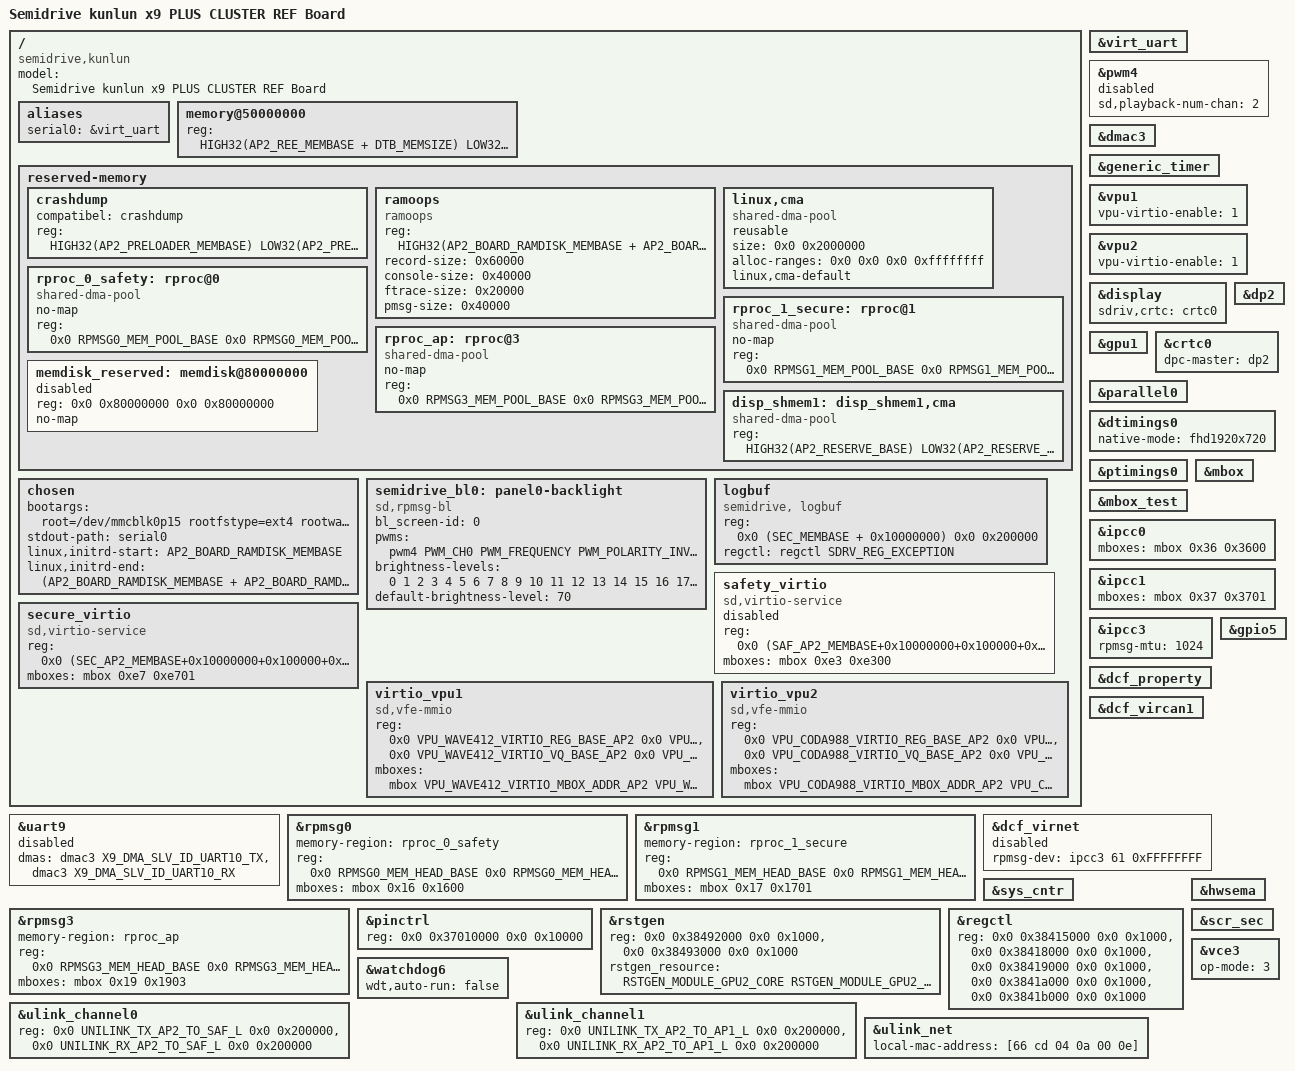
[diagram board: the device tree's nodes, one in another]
/*
 * Semidrive kunlun platform DTS file
 *
 * Copyright (C) 2019, Semidrive  Communications Inc.
 *
 * This file is licensed under a dual GPLv2 or X11 license.
 */

/dts-v1/;

#include "x9_high-plus_cluster.dtsi"
#include "x9_high-plus_ref_cluster-clk-ctrl.dtsi"
#include "lcd-timings.dtsi"
#include <dt-bindings/pinctrl/pins-sdx9.h>
#include <dt-bindings/memmap/x9_high-plus/projects/serdes_virt_emmc/image_cfg.h>
#include <dt-bindings/rpmsg/sd,x9hp-ap2.h>
#include <dt-bindings/backlight/sdrv_backlight.h>
#include <dt-bindings/memmap/mem_share.h>
#include <dt-bindings/soc/sdrv-virtio.h>
#include <dt-bindings/soc/sdrv-unilink-x9hp.h>

/ {
	model = "Semidrive kunlun x9 PLUS CLUSTER REF Board";

	compatible = "semidrive,kunlun";

	aliases {
		serial0 = &virt_uart;
	};

	memory@50000000 {
		device_type = "memory";
		reg = <HIGH32(AP2_REE_MEMBASE + DTB_MEMSIZE) LOW32(AP2_REE_MEMBASE + DTB_MEMSIZE) HIGH32(AP2_KERNEL_MEMSIZE) LOW32(AP2_KERNEL_MEMSIZE) \
			HIGH32(AP2_RESERVE_BASE) LOW32(AP2_RESERVE_BASE) HIGH32(AP2_RESERVE_SIZE) LOW32(AP2_RESERVE_SIZE)>;
	};

	reserved-memory {
		#address-cells = <2>;
		#size-cells = <2>;
		ranges;

		crashdump {
			/* reserve preloader mem for crashdump */
			compatibel = "crashdump";
			reg = <HIGH32(AP2_PRELOADER_MEMBASE) LOW32(AP2_PRELOADER_MEMBASE) 0 AP2_PRELOADER_MEMSIZE>;
		};

		ramoops {
			compatible = "ramoops";
			reg = <HIGH32(AP2_BOARD_RAMDISK_MEMBASE + AP2_BOARD_RAMDISK_MEMSIZE + 0x1000000)
				LOW32(AP2_BOARD_RAMDISK_MEMBASE + AP2_BOARD_RAMDISK_MEMSIZE + 0x1000000) 0x0 0x100000>;
			record-size = <0x60000>;
			console-size = <0x40000>;
			ftrace-size = <0x20000>;
			pmsg-size = <0x40000>;
		};

		/* Default Common CMA Pool */
		/* QUIRK: Must be kept in the lower 4096 MiBs of DRAM banks for VE */
		linux,cma {
			compatible = "shared-dma-pool";
			reusable;
			size = <0x0 0x2000000>; /* 32MB */
			/* 4GB maximum in case of 32-bit only capable devices */
			alloc-ranges = <0x0 0x0 0x0 0xffffffff>;
			linux,cma-default;
		};

		rproc_0_safety: rproc@0 {
			compatible = "shared-dma-pool";
			no-map;
			reg = <0x0 RPMSG0_MEM_POOL_BASE 0x0 RPMSG0_MEM_POOL_SIZE>;
		};

		rproc_1_secure: rproc@1 {
			compatible = "shared-dma-pool";
			no-map;
			reg = <0x0 RPMSG1_MEM_POOL_BASE 0x0 RPMSG1_MEM_POOL_SIZE>;
		};

		rproc_ap: rproc@3 {
			compatible = "shared-dma-pool";
			no-map;
			reg = <0x0 RPMSG3_MEM_POOL_BASE 0x0 RPMSG3_MEM_POOL_SIZE>;
		};

		memdisk_reserved: memdisk@80000000 {
			reg = <0x0 0x80000000 0x0 0x80000000>;
			no-map;
			status = "disabled";
		};
		disp_shmem1: disp_shmem1,cma {
		    compatible = "shared-dma-pool";
		    reg = <HIGH32(AP2_RESERVE_BASE) LOW32(AP2_RESERVE_BASE) HIGH32(AP2_RESERVE_SIZE) LOW32(AP2_RESERVE_SIZE)>;
		    status = "okay";
		};
	};

	chosen {
		bootargs = "root=/dev/mmcblk0p15 rootfstype=ext4 rootwait ro highres=1 nr_cpus=1 loglevel=4 console=ttyV0 fbcon=map:1 psplash=false init=/sbin/init";
		stdout-path = "serial0";
		linux,initrd-start = <AP2_BOARD_RAMDISK_MEMBASE>;
		linux,initrd-end   = <(AP2_BOARD_RAMDISK_MEMBASE + AP2_BOARD_RAMDISK_MEMSIZE)>;/* 64MB */
	};

	semidrive_bl0: panel0-backlight {
		compatible = "sd,rpmsg-bl"; /*"sd,rpmsg-bl" for rpmsg; "pwm-backlight" for native*/
		bl_screen-id = /bits/ 32 <0>;
		pwms = <&pwm4 PWM_CH0 PWM_FREQUENCY PWM_POLARITY_INVERSED>;
		brightness-levels = <0 1 2 3 4 5 6 7 8 9 10 11 12 13 14 15 16
							 17 18 19 20 21 22 23 24 25 26 27 28 29 30
							 31 32 33 34 35 36 37 38 39 40 41 42 43 44
							 45 46 47 48 49 50 51 52 53 54 55 56 57 58
							 59 60 61 62 63 64 65 66 67 68 69 70 71 72
							 73 74 75 76 77 78 79 80 81 82 83 84 85 86
							 87 88 89 90 91 92 93 94 95 96 97 98 99 100>;
		default-brightness-level = <70>;
		status = "okay";
	};

	logbuf {
		compatible = "semidrive, logbuf";
		reg = <0x0 (SEC_MEMBASE + 0x10000000) 0x0 0x200000>;
		regctl = <&regctl SDRV_REG_EXCEPTION>;
		status = "okay";
	};

	safety_virtio {
		compatible = "sd,virtio-service";
		reg = <0x0 (SAF_AP2_MEMBASE+0x10000000+0x100000+0x20000) 0x0 0x40000>;
		mboxes = <&mbox 0xe3 0xe300>;
		status = "disabled";
        };

	secure_virtio {
		compatible = "sd,virtio-service";
		reg = <0x0 (SEC_AP2_MEMBASE+0x10000000+0x100000+0x20000) 0x0 0x40000>;
		mboxes = <&mbox 0xe7 0xe701>;
		status = "okay";
	};

	virtio_vpu1 {
		compatible = "sd,vfe-mmio";
		reg = <0x0 VPU_WAVE412_VIRTIO_REG_BASE_AP2 0x0 VPU_WAVE412_VIRTIO_REG_SIZE>,
			<0x0 VPU_WAVE412_VIRTIO_VQ_BASE_AP2 0x0 VPU_WAVE412_VIRTIO_VQ_SIZE>;
		mboxes = <&mbox VPU_WAVE412_VIRTIO_MBOX_ADDR_AP2 VPU_WAVE412_VIRTIO_MBOX_ADDR2_AP2>;
		status = "okay";
	};

	virtio_vpu2 {
		compatible = "sd,vfe-mmio";
		reg = <0x0 VPU_CODA988_VIRTIO_REG_BASE_AP2 0x0 VPU_CODA988_VIRTIO_REG_SIZE>,
			<0x0 VPU_CODA988_VIRTIO_VQ_BASE_AP2 0x0 VPU_CODA988_VIRTIO_VQ_SIZE>;
		mboxes = <&mbox VPU_CODA988_VIRTIO_MBOX_ADDR_AP2 VPU_CODA988_VIRTIO_MBOX_ADDR2_AP2>;
		status = "okay";
	};
};

&virt_uart {
	status = "okay";
};


&pwm4 {
	sd,playback-num-chan = <2>;
	#pwm-cells = <3>;
	status = "disabled";
};

&dmac3 {
	status = "okay";
};

&uart9 {
	dmas = <&dmac3 X9_DMA_SLV_ID_UART10_TX>, <&dmac3 X9_DMA_SLV_ID_UART10_RX>;
	dma-names = "tx", "rx";
	status = "disabled";
};

&generic_timer {
	status = "okay";
};

&vpu1 {
	vpu-virtio-enable = <1>;
	status = "okay";
};

&vpu2 {
	vpu-virtio-enable = <1>;
	status = "okay";
};

&display {
	sdriv,crtc = <&crtc0>;
	status = "okay";
};

&gpu1 {
	status = "okay";
};
&dp2 {
	status = "okay";
};

&crtc0 {
	dpc-master = <&dp2>;
	status = "okay";
};

&parallel0 {
	status = "okay";
};

&dtimings0 {
	native-mode = <&fhd1920x720>;
};

&ptimings0 {
	status = "okay";
};

&mbox {
	status = "okay";
};

&mbox_test {
	status = "okay";
};

&rpmsg0 {
	memory-region = <&rproc_0_safety>;
	reg = <0x0 RPMSG0_MEM_HEAD_BASE 0x0 RPMSG0_MEM_HEAD_SIZE>;
	mboxes = <&mbox 0x16 0x1600>;
	status = "okay";
};

&rpmsg1 {
	memory-region = <&rproc_1_secure>;
	reg = <0x0 RPMSG1_MEM_HEAD_BASE 0x0 RPMSG1_MEM_HEAD_SIZE>;
	mboxes = <&mbox 0x17 0x1701>;
	status = "okay";
};

&rpmsg3 {
	memory-region = <&rproc_ap>;
	reg = <0x0 RPMSG3_MEM_HEAD_BASE 0x0 RPMSG3_MEM_HEAD_SIZE>;
	mboxes = <&mbox 0x19 0x1903>;
	status = "okay";
};

&ipcc0 {
	mboxes = <&mbox 0x36 0x3600>;
	status = "okay";
};

&ipcc1 {
	mboxes = <&mbox 0x37 0x3701>;
	status = "okay";
};

&ipcc3 {
	rpmsg-mtu  = <1024>;
	status = "okay";
};

&dcf_property {
	status = "okay";
};

&dcf_vircan1 {
	status = "okay";
};

&dcf_virnet {
	rpmsg-dev  = <&ipcc3 61 0xFFFFFFFF>;
	status = "disabled";
};

&sys_cntr {
	status = "okay";
};

&pinctrl {
	reg = <0x0 0x37010000 0x0 0x10000>;
};

&gpio5 {
	status = "okay";
};

&rstgen {
	reg = <0x0 0x38492000 0x0 0x1000>,	/* gpu2 core */
		<0x0 0x38493000 0x0 0x1000>;	/* gpu2 ss */

	rstgen_resource = <
		RSTGEN_MODULE_GPU2_CORE
		RSTGEN_MODULE_GPU2_SS

	>;
	status = "okay";
};

&regctl {
	reg = <0x0 0x38415000 0x0 0x1000>,
		<0x0 0x38418000 0x0 0x1000>,
		<0x0 0x38419000 0x0 0x1000>,
		<0x0 0x3841a000 0x0 0x1000>,
		<0x0 0x3841b000 0x0 0x1000>;
	reg-names = "SDRV_REG_REMAP",
			"SDRV_REG_BOOTREASON",
			"SDRV_REG_HWID",
			"SDRV_REG_STATUS",
			"SDRV_REG_EXCEPTION";
	status = "okay";
};

&hwsema {
        status = "okay";
};

&scr_sec {
        status = "okay";
};

&vce3 {
   /*
	* op-mode options:
	* bit 0: rng enable(1) or disable(0)
	* bit 1: ce enable(1) or disable(0)
	*/
	op-mode = <3>;
	status = "okay";
};

&watchdog6 {
	wdt,auto-run = "false";
	status = "okay";
};

&ulink_channel0 {
	reg = <0x0 UNILINK_TX_AP2_TO_SAF_L 0x0 0x200000>,
		<0x0 UNILINK_RX_AP2_TO_SAF_L 0x0 0x200000>;
	status = "okay";
};

&ulink_channel1 {
	reg = <0x0 UNILINK_TX_AP2_TO_AP1_L 0x0 0x200000>,
		<0x0 UNILINK_RX_AP2_TO_AP1_L 0x0 0x200000>;
	status = "okay";
};

&ulink_net {
	local-mac-address = [66 cd 04 0a 00 0e];
	status = "okay";
};
